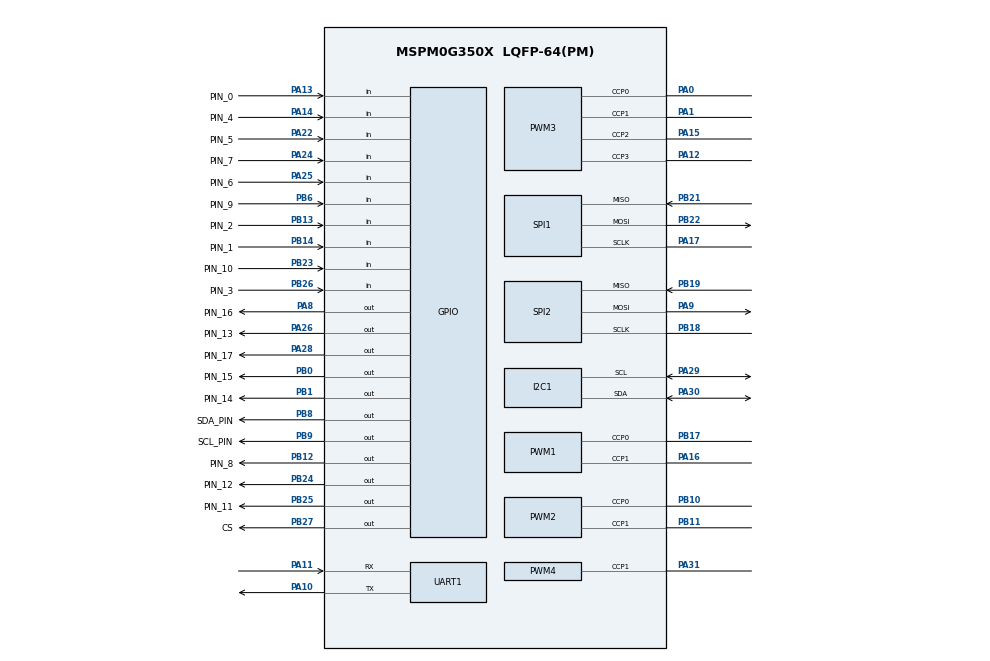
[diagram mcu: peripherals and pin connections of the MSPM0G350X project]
/**
 * @cliArgs --device "MSPM0G350X" --part "Default" --package "LQFP-64(PM)" --product "mspm0_sdk@2.02.00.05"
 * @versions {"tool":"1.21.1+3772"}
 */

/**
 * Import the modules used in this configuration.
 */
const ADC12  = scripting.addModule("/ti/driverlib/ADC12", {}, false);
const ADC121 = ADC12.addInstance();
const GPIO   = scripting.addModule("/ti/driverlib/GPIO", {}, false);
const GPIO1  = GPIO.addInstance();
const GPIO2  = GPIO.addInstance();
const GPIO3  = GPIO.addInstance();
const GPIO4  = GPIO.addInstance();
const GPIO5  = GPIO.addInstance();
const GPIO6  = GPIO.addInstance();
const GPIO7  = GPIO.addInstance();
const GPIO8  = GPIO.addInstance();
const GPIO9  = GPIO.addInstance();
const GPIO10 = GPIO.addInstance();
const GPIO11 = GPIO.addInstance();
const GPIO12 = GPIO.addInstance();
const GPIO13 = GPIO.addInstance();
const GPIO14 = GPIO.addInstance();
const GPIO15 = GPIO.addInstance();
const GPIO16 = GPIO.addInstance();
const GPIO17 = GPIO.addInstance();
const GPIO18 = GPIO.addInstance();
const GPIO19 = GPIO.addInstance();
const GPIO20 = GPIO.addInstance();
const GPIO21 = GPIO.addInstance();
const I2C    = scripting.addModule("/ti/driverlib/I2C", {}, false);
const I2C1   = I2C.addInstance();
const PWM    = scripting.addModule("/ti/driverlib/PWM", {}, false);
const PWM1   = PWM.addInstance();
const PWM2   = PWM.addInstance();
const PWM3   = PWM.addInstance();
const PWM4   = PWM.addInstance();
const SPI    = scripting.addModule("/ti/driverlib/SPI", {}, false);
const SPI1   = SPI.addInstance();
const SPI2   = SPI.addInstance();
const SYSCTL = scripting.addModule("/ti/driverlib/SYSCTL");
const TIMER  = scripting.addModule("/ti/driverlib/TIMER", {}, false);
const TIMER1 = TIMER.addInstance();
const UART   = scripting.addModule("/ti/driverlib/UART", {}, false);
const UART1  = UART.addInstance();

/**
 * Write custom configuration values to the imported modules.
 */
const gate7  = system.clockTree["MFCLKGATE"];
gate7.enable = true;

ADC121.$name                          = "ADC12_0";
ADC121.repeatMode                     = true;
ADC121.sampleTime0                    = "3.14us";
ADC121.configureDMA                   = true;
ADC121.enabledDMATriggers             = ["DL_ADC12_DMA_MEM0_RESULT_LOADED"];
ADC121.peripheral.$assign             = "ADC0";
ADC121.peripheral.adcPin0.$assign     = "PA27";
ADC121.adcPin0Config.$name            = "ti_driverlib_gpio_GPIOPinGeneric18";
ADC121.DMA_CHANNEL.$name              = "DMA_CH0";
ADC121.DMA_CHANNEL.peripheral.$assign = "DMA_CH0";

const Board = scripting.addModule("/ti/driverlib/Board", {}, false);

GPIO1.$name                          = "SDA";
GPIO1.associatedPins[0].$name        = "SDA_PIN";
GPIO1.associatedPins[0].initialValue = "SET";
GPIO1.associatedPins[0].pin.$assign  = "PB8";

GPIO2.$name                          = "SCL";
GPIO2.associatedPins[0].$name        = "SCL_PIN";
GPIO2.associatedPins[0].initialValue = "SET";
GPIO2.associatedPins[0].pin.$assign  = "PB9";

GPIO3.$name                               = "B1";
GPIO3.associatedPins[0].$name             = "PIN_0";
GPIO3.associatedPins[0].direction         = "INPUT";
GPIO3.associatedPins[0].interruptEn       = true;
GPIO3.associatedPins[0].polarity          = "RISE";
GPIO3.associatedPins[0].interruptPriority = "1";
GPIO3.associatedPins[0].internalResistor  = "PULL_UP";
GPIO3.associatedPins[0].pin.$assign       = "PA13";

GPIO4.$name                               = "B2";
GPIO4.associatedPins[0].$name             = "PIN_1";
GPIO4.associatedPins[0].direction         = "INPUT";
GPIO4.associatedPins[0].interruptEn       = true;
GPIO4.associatedPins[0].polarity          = "RISE";
GPIO4.associatedPins[0].interruptPriority = "1";
GPIO4.associatedPins[0].internalResistor  = "PULL_UP";
GPIO4.associatedPins[0].pin.$assign       = "PB14";

GPIO5.$name                               = "B3";
GPIO5.associatedPins[0].$name             = "PIN_2";
GPIO5.associatedPins[0].direction         = "INPUT";
GPIO5.associatedPins[0].interruptEn       = true;
GPIO5.associatedPins[0].interruptPriority = "1";
GPIO5.associatedPins[0].polarity          = "RISE";
GPIO5.associatedPins[0].internalResistor  = "PULL_UP";
GPIO5.associatedPins[0].pin.$assign       = "PB13";

GPIO6.$name                               = "B4";
GPIO6.associatedPins[0].$name             = "PIN_3";
GPIO6.associatedPins[0].direction         = "INPUT";
GPIO6.associatedPins[0].interruptEn       = true;
GPIO6.associatedPins[0].interruptPriority = "1";
GPIO6.associatedPins[0].polarity          = "RISE";
GPIO6.associatedPins[0].internalResistor  = "PULL_UP";
GPIO6.associatedPins[0].pin.$assign       = "PB26";

GPIO7.$name                               = "B5";
GPIO7.associatedPins[0].$name             = "PIN_4";
GPIO7.associatedPins[0].direction         = "INPUT";
GPIO7.associatedPins[0].interruptEn       = true;
GPIO7.associatedPins[0].interruptPriority = "1";
GPIO7.associatedPins[0].polarity          = "RISE";
GPIO7.associatedPins[0].internalResistor  = "PULL_UP";
GPIO7.associatedPins[0].pin.$assign       = "PA14";

GPIO8.$name                               = "B6";
GPIO8.associatedPins[0].$name             = "PIN_5";
GPIO8.associatedPins[0].direction         = "INPUT";
GPIO8.associatedPins[0].interruptEn       = true;
GPIO8.associatedPins[0].interruptPriority = "1";
GPIO8.associatedPins[0].polarity          = "RISE";
GPIO8.associatedPins[0].internalResistor  = "PULL_UP";
GPIO8.associatedPins[0].pin.$assign       = "PA22";

GPIO9.$name                               = "B7";
GPIO9.associatedPins[0].$name             = "PIN_6";
GPIO9.associatedPins[0].direction         = "INPUT";
GPIO9.associatedPins[0].interruptEn       = true;
GPIO9.associatedPins[0].interruptPriority = "1";
GPIO9.associatedPins[0].polarity          = "RISE";
GPIO9.associatedPins[0].internalResistor  = "PULL_UP";
GPIO9.associatedPins[0].pin.$assign       = "PA25";

GPIO10.$name                               = "B8";
GPIO10.associatedPins[0].$name             = "PIN_7";
GPIO10.associatedPins[0].direction         = "INPUT";
GPIO10.associatedPins[0].interruptEn       = true;
GPIO10.associatedPins[0].interruptPriority = "1";
GPIO10.associatedPins[0].polarity          = "RISE";
GPIO10.associatedPins[0].internalResistor  = "PULL_UP";
GPIO10.associatedPins[0].pin.$assign       = "PA24";

GPIO11.$name                              = "PC817";
GPIO11.associatedPins[0].$name            = "PIN_8";
GPIO11.associatedPins[0].initialValue     = "SET";
GPIO11.associatedPins[0].internalResistor = "PULL_UP";
GPIO11.associatedPins[0].pin.$assign      = "PB12";

GPIO12.$name                          = "ICM42688";
GPIO12.associatedPins[0].$name        = "CS";
GPIO12.associatedPins[0].initialValue = "SET";
GPIO12.associatedPins[0].pin.$assign  = "PB27";

GPIO13.$name                              = "key1";
GPIO13.associatedPins[0].$name            = "PIN_9";
GPIO13.associatedPins[0].direction        = "INPUT";
GPIO13.associatedPins[0].internalResistor = "PULL_UP";
GPIO13.associatedPins[0].pin.$assign      = "PB6";

GPIO14.$name                              = "key2";
GPIO14.associatedPins[0].$name            = "PIN_10";
GPIO14.associatedPins[0].direction        = "INPUT";
GPIO14.associatedPins[0].internalResistor = "PULL_UP";
GPIO14.associatedPins[0].pin.$assign      = "PB23";

GPIO15.$name                          = "NRF_CSN";
GPIO15.associatedPins[0].$name        = "PIN_11";
GPIO15.associatedPins[0].initialValue = "SET";
GPIO15.associatedPins[0].pin.$assign  = "PB25";

GPIO16.$name                         = "NRF_CE";
GPIO16.associatedPins[0].$name       = "PIN_12";
GPIO16.associatedPins[0].pin.$assign = "PB24";

GPIO17.$name                              = "AD0";
GPIO17.associatedPins[0].$name            = "PIN_13";
GPIO17.associatedPins[0].internalResistor = "PULL_DOWN";
GPIO17.associatedPins[0].pin.$assign      = "PA26";

GPIO18.$name                              = "AD1";
GPIO18.associatedPins[0].$name            = "PIN_14";
GPIO18.associatedPins[0].internalResistor = "PULL_DOWN";
GPIO18.associatedPins[0].pin.$assign      = "PB1";

GPIO19.$name                              = "AD2";
GPIO19.associatedPins[0].$name            = "PIN_15";
GPIO19.associatedPins[0].internalResistor = "PULL_DOWN";
GPIO19.associatedPins[0].pin.$assign      = "PB0";

GPIO20.$name                         = "LED1";
GPIO20.associatedPins[0].$name       = "PIN_16";
GPIO20.associatedPins[0].pin.$assign = "PA8";

GPIO21.$name                         = "LED2";
GPIO21.associatedPins[0].$name       = "PIN_17";
GPIO21.associatedPins[0].pin.$assign = "PA28";

I2C1.$name                         = "I2C_0";
I2C1.basicEnableController         = true;
I2C1.peripheral.$assign            = "I2C1";
I2C1.peripheral.sdaPin.$assign     = "PA30";
I2C1.peripheral.sclPin.$assign     = "PA29";
I2C1.sdaPinConfig.$name            = "ti_driverlib_gpio_GPIOPinGeneric13";
I2C1.sdaPinConfig.enableConfig     = true;
I2C1.sdaPinConfig.internalResistor = "PULL_UP";
I2C1.sclPinConfig.$name            = "ti_driverlib_gpio_GPIOPinGeneric14";
I2C1.sclPinConfig.enableConfig     = true;
I2C1.sclPinConfig.internalResistor = "PULL_UP";

PWM1.$name                      = "PWM_0";
PWM1.clockDivider               = 2;
PWM1.timerStartTimer            = true;
PWM1.pwmMode                    = "EDGE_ALIGN_UP";
PWM1.peripheral.$assign         = "TIMA1";
PWM1.peripheral.ccp0Pin.$assign = "PB17";
PWM1.peripheral.ccp1Pin.$assign = "PA16";
PWM1.PWM_CHANNEL_0.$name        = "ti_driverlib_pwm_PWMTimerCC0";
PWM1.PWM_CHANNEL_1.$name        = "ti_driverlib_pwm_PWMTimerCC1";
PWM1.ccp0PinConfig.$name        = "ti_driverlib_gpio_GPIOPinGeneric0";
PWM1.ccp1PinConfig.$name        = "ti_driverlib_gpio_GPIOPinGeneric1";

PWM2.$name                      = "PWM_1";
PWM2.clockDivider               = 2;
PWM2.timerStartTimer            = true;
PWM2.pwmMode                    = "EDGE_ALIGN_UP";
PWM2.peripheral.$assign         = "TIMG8";
PWM2.peripheral.ccp0Pin.$assign = "PB10";
PWM2.peripheral.ccp1Pin.$assign = "PB11";
PWM2.PWM_CHANNEL_0.$name        = "ti_driverlib_pwm_PWMTimerCC2";
PWM2.PWM_CHANNEL_1.$name        = "ti_driverlib_pwm_PWMTimerCC3";
PWM2.ccp0PinConfig.$name        = "ti_driverlib_gpio_GPIOPinGeneric2";
PWM2.ccp1PinConfig.$name        = "ti_driverlib_gpio_GPIOPinGeneric3";

PWM3.$name                      = "PWM_2";
PWM3.clockDivider               = 2;
PWM3.timerStartTimer            = true;
PWM3.ccIndex                    = [0,1,2,3];
PWM3.pwmMode                    = "EDGE_ALIGN_UP";
PWM3.peripheral.$assign         = "TIMA0";
PWM3.peripheral.ccp0Pin.$assign = "PA0";
PWM3.peripheral.ccp1Pin.$assign = "PA1";
PWM3.peripheral.ccp2Pin.$assign = "PA15";
PWM3.peripheral.ccp3Pin.$assign = "PA12";
PWM3.PWM_CHANNEL_0.$name        = "ti_driverlib_pwm_PWMTimerCC4";
PWM3.PWM_CHANNEL_1.$name        = "ti_driverlib_pwm_PWMTimerCC5";
PWM3.ccp0PinConfig.$name        = "ti_driverlib_gpio_GPIOPinGeneric4";
PWM3.ccp1PinConfig.$name        = "ti_driverlib_gpio_GPIOPinGeneric5";
PWM3.PWM_CHANNEL_2.$name        = "ti_driverlib_pwm_PWMTimerCC6";
PWM3.PWM_CHANNEL_3.$name        = "ti_driverlib_pwm_PWMTimerCC7";
PWM3.ccp2PinConfig.$name        = "ti_driverlib_gpio_GPIOPinGeneric6";
PWM3.ccp3PinConfig.$name        = "ti_driverlib_gpio_GPIOPinGeneric7";

PWM4.$name                      = "PWM_3";
PWM4.ccIndex                    = [1];
PWM4.timerStartTimer            = true;
PWM4.pwmMode                    = "EDGE_ALIGN_UP";
PWM4.peripheral.$assign         = "TIMG7";
PWM4.peripheral.ccp1Pin.$assign = "PA31";
PWM4.ccp1PinConfig.$name        = "ti_driverlib_gpio_GPIOPinGeneric20";
PWM4.PWM_CHANNEL_1.$name        = "ti_driverlib_pwm_PWMTimerCC8";

SPI1.$name                      = "SPI_0";
SPI1.frameFormat                = "MOTO3";
SPI1.profile                    = "CONFIG_PROFILE_2";
SPI1.peripheral.$assign         = "SPI1";
SPI1.peripheral.sclkPin.$assign = "PA17";
SPI1.peripheral.mosiPin.$assign = "PB22";
SPI1.peripheral.misoPin.$assign = "PB21";
SPI1.sclkPinConfig.$name        = "ti_driverlib_gpio_GPIOPinGeneric10";
SPI1.mosiPinConfig.$name        = "ti_driverlib_gpio_GPIOPinGeneric11";
SPI1.misoPinConfig.$name        = "ti_driverlib_gpio_GPIOPinGeneric12";

SPI2.$name                      = "SPI_1";
SPI2.frameFormat                = "MOTO3";
SPI2.peripheral.$assign         = "SPI0";
SPI2.peripheral.sclkPin.$assign = "PB18";
SPI2.peripheral.mosiPin.$assign = "PA9";
SPI2.peripheral.misoPin.$assign = "PB19";
SPI2.sclkPinConfig.$name        = "ti_driverlib_gpio_GPIOPinGeneric15";
SPI2.mosiPinConfig.$name        = "ti_driverlib_gpio_GPIOPinGeneric16";
SPI2.misoPinConfig.$name        = "ti_driverlib_gpio_GPIOPinGeneric17";

SYSCTL.forceDefaultClkConfig = true;
SYSCTL.clockTreeEn           = true;

TIMER1.$name              = "TIMER_0";
TIMER1.timerClkDiv        = 8;
TIMER1.timerStartTimer    = true;
TIMER1.timerMode          = "PERIODIC_UP";
TIMER1.interrupts         = ["ZERO"];
TIMER1.interruptPriority  = "1";
TIMER1.timerPeriod        = "0.002";
TIMER1.peripheral.$assign = "TIMG6";

UART1.$name                    = "UART_0";
UART1.targetBaudRate           = 115200;
UART1.peripheral.$assign       = "UART0";
UART1.peripheral.rxPin.$assign = "PA11";
UART1.peripheral.txPin.$assign = "PA10";
UART1.txPinConfig.$name        = "ti_driverlib_gpio_GPIOPinGeneric8";
UART1.rxPinConfig.$name        = "ti_driverlib_gpio_GPIOPinGeneric9";

/**
 * Pinmux solution for unlocked pins/peripherals. This ensures that minor changes to the automatic solver in a future
 * version of the tool will not impact the pinmux you originally saw.  These lines can be completely deleted in order to
 * re-solve from scratch.
 */
Board.peripheral.$suggestSolution          = "DEBUGSS";
Board.peripheral.swclkPin.$suggestSolution = "PA20";
Board.peripheral.swdioPin.$suggestSolution = "PA19";
